# apollo510 register map
Vendor: Ambiq Micro; Series: Apollo; File version: 1.0
CPU: CM55 r1p1, little endian, MPU, FPU, double-precision FPU, DSP, I-cache, D-cache, VTOR, ITCM, DTCM, 4 interrupt priority bits, 0 interrupts, 8 SAU regions
Registers are 32-bit, read-write, reset 0x0 unless marked. A register's access mark holds for its fields unless they carry their own. Offsets are from the block's base; [hi:lo] are bit positions; {n}, {i} and the like mark numbered series; 'fields as' and 'values as' point back to an identical list.

## USB — USB device register descriptions.
Base 0x400B0000
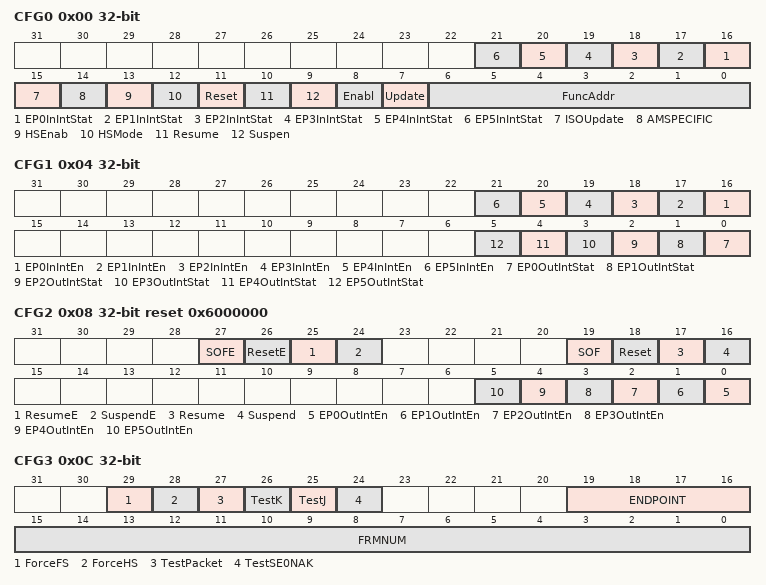
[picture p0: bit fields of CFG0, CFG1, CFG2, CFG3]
0x00 CFG0 — Function address, power management, interrupt status register for EP0 and IN Endpoints 1 to 5
  [n+16] EP{n}InIntStat (n=0..5) — IN Endpoint {n} interrupt status. All interrupts are cleared when the register is read.
    0=INACTIVE (Interrupt inactive.); 1=ACTIVE (Interrupt active.)
  [15] ISOUpdate — Isochronous Transfer Update. When set by the CPU, the USB Controller will wait for an SOF token from the time InPktRdy is set before sending the packet. If an IN token is received before an SOF token, then a zero length data packet will be sent. Note: This bit only affects endpoints performing Isochronous transfers. The ISOUpdate bit affects all IN Isochronous endpoints in the USB Controller. It is normally used as a method of ensuring 'clean' start-up of an IN Isochronous pipe.
    0=DONT_WAIT (Clear for USB Controller not to wait for SOF token before sending packet.); 1=WAIT (Set to have USB Controller wait for SOF token before sending packet.)
  [14] AMSPECIFIC — Software-enabled Connection (SoftConn). When set to 1, the PHY is placed in its normal mode and the D+/D- lines of the USB bus are enabled. When bit is cleared, the PHY is put into non-driving mode and D+ and D- are tri-stated.
    0=NOT_CONNECTED (Clear to disable/disconnect USB lines.); 1=CONNECTED (Set to enable USB lines.)
  [13] HSEnab — High-speed Enable. When set by the CPU, the USB Controller will negotiate for high-speed mode when the device is reset by the hub. If not set, the device will only operate in Full-speed mode. The HSEnab bit can be used to disable high-speed operation. Normally the USB Controller will automatically negotiate for high speed operation, when it is reset, by sending a 'chirp' to the hub. However if this bit is cleared then the USB Controller will not send any 'chirps' to the hub so the function will remain in Full-speed mode, even when connected to a high-speed-capable USB.
    0=DIS_HS (Clear to disable High-speed mode (Full-speed mode only).); 1=EN_HS (Set to enable High-speed mode.)
  [12] HSMode — This read-only bit is set when the USB Controller has successfully negotiated for High-speed mode. The HSMode bit can be used to determine whether the USB Controller is in High-speed mode or Full-speed mode. It will go high when the function has successfully negotiated for high-speed operation during a USB reset.
    0=FS_MODE (Indicates USB Controller is in Full-speed mode only.); 1=HS_MODE (Indicates USB Controller is in High-speed mode.)
  [11] Reset — Reset Status. Cleared when either HS negotiation has completed successfully or after 2.1 ms of reset signaling if HS negotiation fails. The Reset bit can be used to determine when reset signaling is present on the USB. Set when Reset signaling is detected and remains high until the bus reverts to an idle state.
    0=NEG_RESET_COMPLETE (Indicates that HS negotiation has completed successfully, or 2.1 ms of reset signaling has elapsed.); 1=RESETTING (Indicates that Reset signaling is detected and remains high until the bus reverts to an idle state.)
  [10] Resume — Resume. Set should clear this bit after 10 ms (a maximum of 15 ms) to end Resume signaling. The Resume bit is used to force the USB Controller to generate Resume signaling on the USB to perform remote wake-up from Suspend mode. Once set high, it should be left high for approximately 10 ms (at least 1 ms and no more than 15 ms), then cleared.
    0=END_RESUME (Cleared automatically 10-15 ms after being manually set.); 1=RESUME (Set to force USB Controller to generate Resume signal on the USB to cause remote wake-up from Suspend mode.)
  [9] Suspen — Suspend Status. This read-only bit is set when Suspend mode is entered. It is cleared when the CPU reads the interrupt register, or sets the Resume bit of this register. The Suspen bit is set by the USB Controller when Suspend mode is entered. It will be cleared when the CFG2_Suspend field is read (as a result of receiving a Suspend interrupt). It will also be cleared if Suspend mode is left by setting the Resume bit to initiate a remote wake-up.
    0=RESUMED (Indicates that Suspend Mode exited.); 1=SUSPENDED (Indicates that Suspend Mode entered.)
  [8] Enabl — Set by the CPU to enable the SUSPENDM signal. The Enabl bit is set to enable the SUSPENDM signal to put the UTM (and any other hardware which uses the SUSPENDM signal) into Suspend mode. If this bit is not set, Suspend mode will be detected as normal but the SUSPENDM signal will remain high so that the UTM does not go into its low-power mode.
    0=DISABLE_SUSPENDM (Clear to disable SUSPENDM signal - UTM does not go into its low-power mode.); 1=ENABLE_SUSPENDM (Set to enable the SUSPENDM signal to put the UTM (and any other HW which uses the SUSPENDM signal) into Suspend mode.)
  [7] Update — Function Address Update. Set when FuncAddr is written. Cleared when the new address takes effect (at the end of the current transfer).
    0=NEW_ADDR_SET (Indicates that the new address has taken effect.); 1=NEW_ADDR_WRITTEN (Indicates that a new function address has been written to the FuncAddr field.)
  [6:0] FuncAddr — The function address. This field should be written with the address value contained in the SET_ADDRESS standard device request, when it is received on Endpoint 0. The new address will not take effect immediately as the host will still be using the old address for the Status stage of the device request. The USB Controller will continue to use the old address for decoding packets until the device request has completed. The status of the device request can be determined by reading the Update bit. When a new address is written to this field, the Update bit will be automatically set. It will remain high until the device request has completed and will be cleared when the new address takes effect Note: While the firmware may write the new address to the FuncAddr field immediately when it is received, it is recommended to leave this operation to the Status phase of the operation in case the host aborts the command.
0x04 CFG1 — Indicates which of the IN Endpoint 1 - 5 interrupts and the single Endpoint 0 interrupt are currently active. Also indicates which of the interrupts for OUT Endpoint 1 - 5 are currently active. All active interrupts are cleared when this register is read.
  [n+16] EP{n}InIntEn (n=0..5) — IN Endpoint {n} Interrupt Enable
    0=DIS (IN Endpoint interrupt disabled.); 1=EN (IN Endpoint interrupt enabled.)
  [n] EP{n}OutIntStat (n=0..5) — OUT Endpoint {n} interrupt status. All interrupts are cleared when the register is read.
    values as CFG0.EP0InIntStat
0x08 CFG2 reset 0x6000000 — Provides interrupt enable and (currently active) status bits for each of the state interrupts, as well as the IN Endpoint and OUT Endpoint nterrupts. All active interrupts are cleared when this register is read. On reset, all IN and OUT Endpoint interrupts, in addition to Endpoint 0, are set to 1 while the remaining bits are set to 0.
  [27] SOFE — Start of Frame interrupt enable.
    0=DIS (SOF interrupt disable.); 1=EN (SOF interrupt enable.)
  [26] ResetE — Reset Detect Interrupt Enable.
    0=DIS (Reset detect interrupt disable.); 1=EN (Reset detect interrupt enable.)
  [25] ResumeE — Resume Interrupt Enable.
    0=DIS (Resume interrupt disable.); 1=EN (Resume interrupt enable.)
  [24] SuspendE — Suspend Interrupt Enable.
    0=DIS (Suspend interrupt disable.); 1=EN (Suspend interrupt enable.)
  [19] SOF — Start of Frame Interrupt Status. Set at the start of frame.
    0=SOF_INACTIVE (SOF interrupt inactive.); 1=SOF_ACTIVE (SOF interrupt active.)
  [18] Reset — Reset Detect Interrupt Status. Set when reset signaling is detected on the bus.
    0=RESET_INACTIVE (Reset Detect interrupt inactive.); 1=RESET_ACTIVE (Reset Detect interrupt active.)
  [17] Resume — Resume Interrupt Status. Set when resume signaling is detected on the bus while the USB Controller is in Suspend mode.
    0=RESUME_INACTIVE (Resume interrupt inactive.); 1=RESUME_ACTIVE (Resume interrupt active.)
  [16] Suspend — Suspend Interrupt Status. Set when suspend signaling is detected on the bus.
    0=SUSPEND_INACTIVE (Suspend interrupt inactive.); 1=SUSPEND_ACTIVE (Suspend interrupt active.)
  [n] EP{n}OutIntEn (n=0..5) — Out Endpoint {n} Interrupt Enable.
    0=DIS (Out Endpoint interrupt disabled.); 1=EN (Out Endpoint interrupt enabled.)
0x0C CFG3 — Provides Test fields to put the USB Controller into one of four test modes described in the USB 2.0 specification. Only one of the Test fields should be set at any time. (Not used in normal operation.) Also includes an index field that determines which endpoint control,status registers are accessed via the IDXn register fields, and a Frame field that holds the last received frame number.
  [29] ForceFS — Force Full-speed Mode. The CPU sets this bit to force the USB Controller into Full-speed mode when it receives a USB reset.
    0=FS_NOT_FORCED (Do not force FS mode upon USB reset.); 1=FS_FORCED (Force FS mode upon USB reset.)
  [28] ForceHS — Force High-speed Mode. The CPU sets this bit to force the USB Controller into High-speed mode when it receives a USB reset.
    0=HS_NOT_FORCED (Do not force HS mode upon USB reset.); 1=HS_FORCED (Force HS mode upon USB reset.)
  [27] TestPacket — Test Packet Test Mode. The CPU sets this bit to enter the Test_Packet test mode. In this mode, the USB Controller - in high-speed mode - repetitively transmits on the bus a 53-byte test packet. Note: The 53-byte test packet must be loaded into the Endpoint 0 FIFO before the test mode is entered.
    0=STOP_TPTM (Terminates Test Packet Test Mode.); 1=START_TPTM (Initiates Test Packet Test Mode.)
  [26] TestK — Test_K Test Mode. The CPU sets this bit to enter the Test_K test mode. In this mode, the USB Controller - in high-speed mode - transmits a continuous K on the bus.
    0=STOP_TESTK (Terminates Test_K Test Mode.); 1=START_TESTK (Initiates Test_K Test Mode.)
  [25] TestJ — Test_J Test Mode. The CPU sets this bit to enter the Test_J test mode. In this mode, the USB Controller - in high-speed mode - transmits a continuous J on the bus.
    0=STOP_TESTJ (Terminates Test_J Test Mode.); 1=START_TESTJ (Initiates Test_J Test Mode.)
  [24] TestSE0NAK — Test_SE0_NAK Test Mode. The CPU sets this bit to enter the Test_SE0_NAK test mode. In this mode, the USB Controller remains in high-speed mode and responds to any valid IN token with a NAK.
    0=STOP_TESTSE0NAK (Terminates Test_SE0_NAK Test Mode.); 1=START_TESTSE0NAK (Initiates Test_SE0_NAK Test Mode.)
  [19:16] ENDPOINT — Index selected endpoint.
    {v}=Endpoint {v} selected (v=0..5)
  [15:0] FRMNUM — Frame Number. Read-only field containing the last received frame number in bits 10:0, 15:11 read 0.
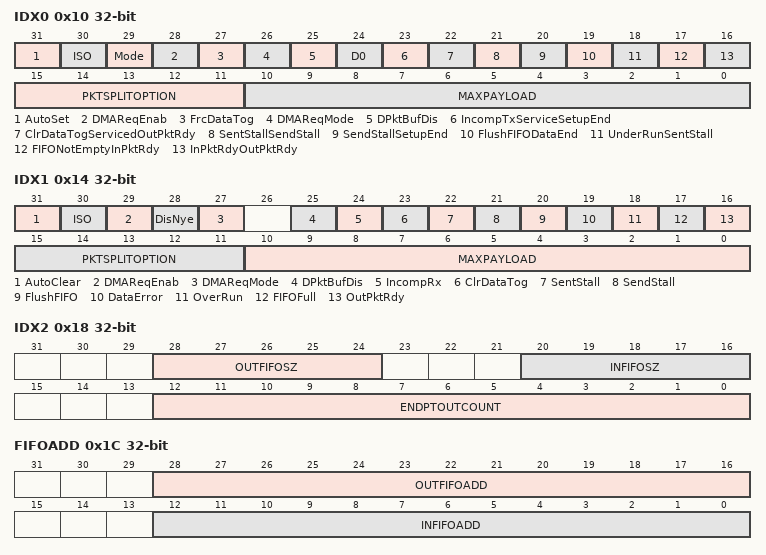
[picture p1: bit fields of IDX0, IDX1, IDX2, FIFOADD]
0x10 IDX0 — Provides additional control and status for IN transactions through the currently-selected endpoint. (To avoid CMSIS conflicts, the address here includes an additional offset of 0x1000. Access to this register must take this into account.) The value returned when this register is read reflects the status of an endpoint specified by setting the endpoint index in the CFG3_ENDPOINT field. When the endpoint index (CFG3_ENDPOINT) == 0, this field provides status and control of Endpoint 0. Also, the MAXPAYLOAD field defines the maximum amount of data that can be transferred through the selected IN endpoint in a single operation. There is a MAXPAYLOAD for each IN endpoint (except Endpoint 0). Note that the action initiated by setting a field in one of the IDXn registers when the selected endpoint has not been configured is undefined.
  [31] AutoSet — Automatically Set InPktRdy. When set, the FIFONotEmptyInPktRdy field (for IN Endpoint 0) or InPktRdyOutPktRdy field (for IN Endpoint 1-5) in this register will be automatically set when data of the maximum packet size (set in MAXPAYLOAD field) is loaded into the IN FIFO.
    0=NO_AUTOSET (InPktRdy field is not automatically set when MAXPAYLOAD data size is loaded into the IN FIFO.); 1=AUTOSET (Applicable InPktRdy field is automatically set when MAXPAYLOAD data size is loaded into the IN FIFO. If a packet of less than the maximum packet size is loaded, InPktRdy will have to be set manually. Note: Should not be set for high-bandwidth Isochronous endpoints.)
  [30] ISO — Isochronous Transfers. The CPU sets this bit to enable the IN endpoint for Isochronous transfers (ISO mode) or for Bulk/Interrupt transfers.
    0=BULK_INT (Clear to enable the IN endpoint for Bulk/Interrupt transfers.); 1=ISO (Set to enable the IN endpoint for Isochronous transfers.)
  [29] Mode — OUT/IN Mode. The CPU sets this bit to enable the endpoint direction as IN or OUT. Note: Only valid where the endpoint FIFO is used for both IN and OUT transactions, otherwise ignored.
    0=OUT (Clear to enable the OUT direction for endpoint.); 1=IN (Set to enable the IN direction for endpoint.)
  [28] DMAReqEnab — The CPU sets this bit to enable the DMA request for the IN endpoint.
  [27] FrcDataTog — Force Data Toggle. The CPU sets this bit to force the endpoint's IN data toggle to switch after each data packet is sent regardless of whether an ACK was received. This can be used by Interrupt IN endpoints that are used to communicate rate feedback for Isochronous endpoints.
    0=NO_FORCE_TOGGLE (Keep cleared to not force data toggle.); 1=FORCE_TOGGLE (Set to force the endpoint's IN data toggle to switch after each data packet is sent.)
  [26] DMAReqMode — The CPU sets this bit to select DMA Request Mode 1 and clears it to select DMA Request Mode 0. Note: This bit must not be cleared either before or in the same cycle as the above DMAReqEnab bit is cleared.
  [25] DPktBufDis — Double Packet Buffer Disable. This bit is used to control the use of Double Packet Buffering. It is ignored when Dynamic FIFO sizing is enabled. Clearing this bit does NOT necessarily enable Double Packet Buffering but rather allows Double Packet Buffering to be determined by the Endpoint's IDX2_INFIFOSZ setting and MAXPAYLOAD size relationship. Default is enabled.
    0=EN_DPB (Clear to allow Double Packet Buffering.); 1=DIS_DPB (Set to disable Double Packet Buffering regardless of the End Point FIFO size and MAXPAYLOAD size relationship.)
  [24] D0 — Unused, always return 0.
  [23] IncompTxServiceSetupEnd — Incomplete Transmission / Service Setup End. When CFG3_ENDPOINT is 1 to 5, this bit serves as the IncompTx field. When CFG3_ENDPOINT is 0, this bit serves as the ServiceSetupEnd field.If CFG3_ENDPOINT is 0x1-0x5, then this bit serves as the IncompTx field. If the endpoint is being used for high-bandwidth Isochronous transfers, this bit is set to indicate when a large packet has been split into 2 or 3 packets for transmission but insufficient IN tokens have been received to send all the parts. The remainder of the current packet is then flushed from the FIFO (but any second packet in the FIFO will remain). Note: In anything other than a high bandwidth Isochronous transfer, this bit will always return 0.
    0=NOP (This value is a NOP.); 1=CLR_SETUPEND (Set to clear the SetupEnd bit. This bit is cleared automatically.)
  [22] ClrDataTogServicedOutPktRdy — Clear Data Toggle / Serviced OUT Packet Ready. When CFG3_ENDPOINT is 1 to 5, this bit serves as the ClrDataTog field. When CFG3_ENDPOINT is 0, this bit serves as the ServicedOutPktReady field.If CFG3_ENDPOINT is 0x1-0x5, this bit serves as the ClrDataTog field. Setting this bit resets the endpoint IN data toggle to 0.If CFG3_ENDPOINT is 0x0, this bit serves as the ServicedOutPktReady field. The CPU writes a 1 to this bit to clear the OutPktRdy bit. This bit is cleared automatically.
  [21] SentStallSendStall — Sent Stall / Send Stall. When CFG3_ENDPOINT is 1 to 5, this bit serves as the SentStall field. When CFG3_ENDPOINT is 0, this bit serves as the SendStall function.If CFG3_ENDPOINT is 0x1-0x5, this bit serves as the SentStall field. It is set when a STALL handshake is transmitted. The FIFO is flushed and the InPktRdy bit is cleared. The CPU should clear this bit.If CFG3_ENDPOINT is 0x0, this bit serves as the SendStall field. The CPU sets this bit to terminate the current transaction. The STALL handshake will be transmitted and then this bit will be cleared automatically. Note: This behavior differs from that of the SendStall bits associated with additional IN/OUT endpoints, which need to be cleared by the CPU.
  [20] SendStallSetupEnd — When CFG3_ENDPOINT is 1 to 5, this bit serves as the SendStall field. When CFG3_ENDPOINT is 0, this bit serves as the SetupEnd field.If CFG3_ENDPOINT is 0x1-0x5, this bit serves as the SendStall field. Setting this bit issues a STALL handshake to an IN token. The CPU clears this bit to terminate the stall condition.Note: This bit has no effect when the endpoint is being used for Isochronous transfers.If CFG3_ENDPOINT is 0x0, this bit serves as the SetupEnd field. It is set when a control transaction ends before the DataEnd bit has been set. An interrupt will be generated and the FIFO flushed at this time. The bit is cleared by the CPU writing a 1 to the ServicedSetupEnd bit.
  [19] FlushFIFODataEnd — When CFG3_ENDPOINT is 1 to 5, this bit serves as the FlushFIFO field. When CFG3_ENDPOINT is 0, this bit serves as the DataEnd bit.If CFG3_ENDPOINT is 0x1-0x5, this bit serves as the FlushFIFO field. Setting this bit flushes the next packet to be transmitted from the endpoint IN FIFO. The FIFO pointer is reset and the InPktRdy bit is cleared. May be set simultaneously with InPktRdy to abort the packet that has just been loaded into the FIFO.Note 1: FlushFIFO should only be set when InPktRdy is set (at other times, it may cause data corruption).Note 2: If the FIFO contains two packets, FlushFIFO may need to be set twice to completely clear the FIFO.If CFG3_ENDPOINT is 0x0, this bit serves as the DataEnd bit. Set this bit when (1) setting InPktRdy for the last data packet, (2) clearing OutPktRdy after unloading the last data packet, or (3) setting InPktRdy for a zero length data packet.It is cleared automatically.
  [18] UnderRunSentStall — Under Run / Sent Stall. When CFG3_ENDPOINT is 1 to 5, this bit serves as the UnderRun field. When CFG3_ENDPOINT is 0, this bit serves as the SentStall field.If CFG3_ENDPOINT is 0x1-0x5, this bit serves as the UnderRun field. In ISO mode this bit is set when a zero length data packet is sent after receiving an IN token with the InPktRdy bit not set. In Bulk/Interrupt mode, this bit is set when a NAK is returned in response to an IN token. The CPU should clear this bit.If CFG3_ENDPOINT is 0x0, this bit serves as the SentStall field. This bit is set when a STALL handshake is transmitted. The CPU should clear this bit.
  [17] FIFONotEmptyInPktRdy — FIFO Not Empty / IN Packet Ready. When CFG3_ENDPOINT is 1 to 5, this bit serves as the FIFONotEmpty field. When CFG3_ENDPOINT is 0, this bit serves as the InPktRdy bit.If CFG3_ENDPOINT is 0x1-0x5, this bit serves as the FIFONotEmpty field. It is set when there is at least 1 packet in the IN FIFO.If CFG3_ENDPOINT is 0x0, this bit serves as the InPktRdy bit. Set this bit after loading a data packet into the FIFO. It is cleared automatically when the data packet has been transmitted. An interrupt is generated when this bit is cleared (if enabled).
  [16] InPktRdyOutPktRdy — IN Packet Ready / OUT Packet Ready. When CFG3_ENDPOINT > 0, this bit serves as the InPktRdy field. When CFG3_ENDPOINT is 0, this bit serves as the OutPkyRdy bit.If CFG3_ENDPOINT is 0x1-0x5, this bit serves as the InPktRdy field. Set this bit after loading a data packet into the FIFO. It is cleared automatically when a data packet has been transmitted. If the FIFO is double-buffered, it is also automatically cleared when there is space for a second packet in the FIFO. An interrupt is generate (if enabled) when the bit is cleared.If CFG3_ENDPOINT is 0x0, this bit serves as the OutPkyRdy bit. This bit is set when a data packet has been received. An interrupt is generate when this bit is set (if enabled). The CPU clears this bit by setting the ServicedOutPktRdy bit.
  [15:11] PKTSPLITOPTION — Packet Split Option. When IDX0_ISO is 1, this bit serves as the MAXPAYLOAD multiplier for Isochronous IN transfers. When IDX0_ISO is 0, this bit serves as the MAXPAYLOAD multiplier for Bulk IN transfers.If IDX0_ISO is 0x1, this field sets the multiplier for Isochronous transfers. For Isochronous endpoints operating in High-Speed mode and with the High-bandwidth option enabled, PKTSPLITOPTION may be either 2 or 3 (corresponding to this field's bit 0 set or bit 1 set, respectively, and bits[4:2] are ignored) and it specifies the maximum number of such transactions that can take place in a single microframe. If either bit 0 or bit 1 is non-zero, the USB Controller will automatically split any data packet written to the FIFO into up to 2 or 3 'USB' packets, each containing the specified MAXPAYLOAD (or less). The maximum payload for each transaction is 1024 bytes, so this allows up to 3072 bytes to be transmitted in each microframe. (For Isochronous transfers in full-speed mode or if High-bandwidth is not enabled, bits 0 and 1 are ignored.)If IDX0_ISO is 0x0, this field sets the multiplier for Bulk transfers. The field setting can be up to 31, and the multiplier, m, is (field setting + 1). The multiplier defines the maximum number of 'USB' packets of the specified MAXPAYLOAD data bytes into which a single data packet placed in the FIFO should be split prior to transfer. The data packet is required to be an exact multiple of the MAXPAYLOAD, which is itself required to be either 8, 16, 32, 64 or (in the case of High Speed transfers) 512 bytes.
  [10:0] MAXPAYLOAD — Maximum Payload transmitted in a single transaction. The total amount of data represented by MAXPAYLOAD x (PKTSPLITOPTION + 1) must not exceed the FIFO size for the IN endpoint, and should not exceed half the FIFO size if double-buffering is required. Note: The value written here (multiplied by PKTSPLITOPTION + 1 in the case of high-bandwidth Isochronous transfers) must match the value given in the wMaxPacketSize field of the Standard Endpoint Descriptor for the associated endpoint (see USB Specification Revision 2.0, Chapter 9). A mismatch could cause unexpected results.
0x14 IDX1 — Provides control and status bits for OUT transactions through the currently-selected endpoint. It is reset to 0. The value returned when this register is read reflects the status of an endpoint specified by setting the endpoint index in the CFG3_ENDPOINT field. Also, the MAXPAYLOAD field defines the maximum amount of data that can be transferred through the selected OUT endpoint in a single operation. There is a MAXPAYLOAD for each OUT endpoint (except Endpoint 0). Note that the action initiated by setting a field in one of the IDXn registers when the selected endpoint has not been configured is undefined.
  [31] AutoClear — Automatically Clear OutPktRdy.
    0=NO_AUTOCLR (OutPktRdy field will not be automatically cleared when a packet of MAXPAYLOAD data size is unloaded from the OUT FIFO.); 1=AUTOCLR (OutPktRdy field will be automatically cleared when a packet of MAXPAYLOAD data size is unloaded from the OUT FIFO. When packets of less than the maximum packet size are unloaded, OutPktRdy must be cleared manually. Note: Should not be set for high bandwidth Isochronous endpoints.)
  [30] ISO — Isochronous Transfers. The CPU sets this bit to enable the OUT endpoint for either Isochronous transfers (ISO mode) or for Bulk/Interrupt transfers.
    0=BULK_INT (Clear to enable the OUT endpoint for Bulk/Interrupt transfers.); 1=ISO (Set to enable the OUT endpoint for Isochronous transfers.)
  [29] DMAReqEnab — Set this bit to enable the DMA request for the OUT endpoint.
  [28] DisNye — Disable NYET Handshakes / PID Error. For Bulk/Interrupt transactions, this bit disable the sending of NYET handshakes. For Bulk/Interrupt transactions, indicates PID errors.If IDX1_ISO is 0x1, this field is read-only and, when set, indicates a PID error in the received packet for Isochronous transfers.If IDX1_ISO is 0x0, this field disables NYET Handshakes for Bulk/Interrupt transactions. Set this bit to disable the sending of NYET handshakes. When set, all successfully received OUT packets are ACK'd including at the point at which the FIFO becomes full.Note: This bit has an effect only in High-speed mode, when it should be set for all Interrupt endpoints.
  [27] DMAReqMode — Two modes of DMA Request operation are supported: Set to 0 for DMA Request Mode 0 in which a DMA request is generated for all received packets; set to 1 for DMA Request Mode 1 in which a DMA request (but no interrupt) is generated for OUT packets of size MAXPAYLOAD bytes and an interrupt (but no DMA request) is generated for OUT packets of any other size.
  [25] DPktBufDis — Double Packet Buffer Disable. This bit is used to control the use of Double Packet Buffering. It is ignored when Dynamic FIFO sizing is enabled. Clearing this bit does NOT necessarily enable Double Packet Buffering but rather allows Double Packet Buffering to be determined by the Endpoint's IDX2_OUTFIFOSZ setting and MAXPAYLOAD size relationship. Default is enabled.
    values as IDX0.DPktBufDis
  [24] IncompRx — Incomplete Receive. This bit is set in a high-bandwidth Isochronous transfer if the packet in the OUT FIFO is incomplete because parts of the data were not received. It is cleared when OutPktRdy is cleared. Note: In anything other than a high-bandwidth Isochronous transfer, this bit will always return 0.
  [23] ClrDataTog — Clear Data Toggle. Set this bit to reset the endpoint data toggle to 0.
  [22] SentStall — Sent Stall. This bit is set when a STALL handshake is transmitted. The CPU should clear this bit.
  [21] SendStall — Send Stall. Issues a STALL handshake to a DATA packet.If IDX1_ISO is 0x1, this bit has no effect when the endpoint is being used for Isochronous transfers.If IDX1_ISO is 0x0, this field enables Stall Handshakes for Bulk/Interrupt transactions. Set this bit to issue a STALL handshake to a DATA packet. Clear this bit to terminate the stall condition.
  [20] FlushFIFO — Flush FIFO. Set this bit to flush the next packet to be read from the endpoint OUT FIFO. The FIFO pointer is reset and the OutPktRdy bit is cleared. FlushFIFO should only be used when OutPktRdy is set. At other times, it may cause data to be corrupted. If the FIFO is double-buffered, FlushFIFO may need to be set twice to completely clear the FIFO.
  [19] DataError — Data Error. Indicates a CRC error.If IDX1_ISO is 0x1 (ISO mode), this bit is set at the same time that OutPktRdy is set if the data packet has a CRC error. It is cleared when OutPktRdy is cleared.If IDX1_ISO is 0x0 (Bulk mode), this field always returns zero. This field is only valid when the endpoint is operating in ISO mode.
  [18] OverRun — Overrun Condition. Indicates an overrun.If IDX1_ISO is 0x1 (ISO mode), this bit is set if an OUT packet arrives while FIFOFull is set, i.e., the OUT packet cannot be loaded into the OUT FIFO. The CPU should clear this bit.If IDX1_ISO is 0x0 (Bulk mode), this field always returns zero. This field is only valid when the endpoint is operating in ISO mode.
  [17] FIFOFull — FIFO Full. When set, this bit indicates that no more packets can be loaded into the OUT FIFO.
  [16] OutPktRdy — OUT Packet Ready. This bit is set when a data packet has been received. Clear this bit when the packet has been unloaded from the OUT FIFO. An interrupt is generated (if enabled) when the bit is set.
  [15:11] PKTSPLITOPTION — Packet Split Option. When IDX1_ISO is 1, this bit serves as the MAXPAYLOAD multiplier for Isochronous OUT transfers. When IDX1_ISO is 0, this bit serves as the MAXPAYLOAD multiplier for Bulk IN transfers.If IDX1_ISO is 0x1, this field sets the multiplier for Isochronous transfers. For Isochronous endpoints operating in High-Speed mode and with the High-bandwidth option enabled, PKTSPLITOPTION may be either 2 or 3 (corresponding to this field's bit 0 set or bit 1 set, respectively, and bits[4:2] are ignored) and it specifies the maximum number of such transactions that can take place in a single microframe. If either bit 0 or bit 1 is non-zero, the USB Controller will automatically combine the separate USB packets received in any microframe into a single packet within the OUT FIFO. The maximum payload for each transaction is 1024 bytes, so this allows up to 3072 bytes to be received in each microframe. (For Isochronous transfers in full-speed mode or if high-bandwidth is not enabled, bits 0 and 1 are ignored.)If IDX1_ISO is 0x0, this field sets the multiplier for Bulk transfers. The field setting can be up to 31, and the multiplier, m, is (field setting + 1). The multiplier defines the number of USB packets of the specified payload which are to be combined into a single data packet within the FIFO.
  [10:0] MAXPAYLOAD — Maximum Payload transmitted in a single transaction. The value set can be up to 1024 bytes but is subject to the constraints placed by the USB Specification on packet sizes for Bulk, Interrupt and Isochronous transfers in Fullspeed and High-speed operations. The total amount of data represented by MAXPAYLOAD x (PKTSPLITOPTION + 1) must not exceed the FIFO size for the OUT endpoint, and should not exceed half the FIFO size if double-buffering is required. Note: The value written here (multiplied by m in the case of high-bandwidth Isochronous transfers) must match the value given in the wMaxPacketSize field of the Standard Endpoint Descriptor for the associated endpoint (see USB Specification Revision 2.0, Chapter 9). A mismatch could cause nexpected results.
0x18 IDX2 — Contains the outcount value for number of received bytes in the packet in the OUT FIFO, and the configurable IN and OUT Endpoint FIFO size.
  [28:24] OUTFIFOSZ — OUT FIFO Size. Sets the size of the selected OUT endpoint FIFO. Bit 4 of this field defines whether double-packet buffering is supported. When set, double-packet buffering is supported. When cleared, only single-packet buffering is supported. Bits [3:0] of this field determine maximum packet size, where 2^^(b3:b0 + 3) is the maximum packet size to be allowed (before any splitting within the FIFO of Bulk/High-Bandwidth packets prior to transmission).
  [20:16] INFIFOSZ — IN FIFO Size. Sets the size of the selected IN endpoint FIFO. Bit 4 of this field defines whether double-packet buffering supported. When set, double-packet buffering is supported. When cleared, only single-packet buffering is supported. Bits [3:0] of this field determine maximum packet size, where 2^^(b3:b0 + 3) is the maximum packet size to be allowed (before any splitting within the FIFO of Bulk/High-Bandwidth packets prior to transmission).
  [12:0] ENDPTOUTCOUNT — Endpoint OUT Count. When CFG3_ENDPOINT is 1 to 5, this read-only field holds the number of received data bytes in the packet in the Endpoint's OUT FIFO. When CFG3_ENDPOINT is 0, this read-only field holds 7-bit data for number of received data bytes in Endpoint 0 FIFO (OUT count). In either case, the value returned changes as the contents of the FIFO change and is only valid while OutPktRdy is set. (IMPORTANT: The address for the OUTCOUNT register is actually the same as COUNT0. However to avoid CMSIS conflicts, the address here includes an additional offset of 0x1000. Access to this register must take this into account.)If CFG3_ENDPOINT is 0x1-0x5, this read-only field holds the number of received data bytes in the packet in the OUT FIFO. If the packet was transmitted as multiple bulk packets, the number given will be for the combined packet.If CFG3_ENDPOINT is 0x0, this read-only field holds 7-bit data for number of received data bytes in Endpoint 0 FIFO (OUT count).
0x1C FIFOADD — Sets the start address of the selected IN and OUT endpoint FIFOs.
  [28:16] OUTFIFOADD — Sets the start address of the selected OUT endpoint FIFO.
  [12:0] INFIFOADD — Sets the start address of the selected IN endpoint FIFO.
{0x20+4i} FIFO{i} (i=0..5) — Endpoint {i} FIFO register
  [31:0] FIFO — Writing to this register loads data into the IN FIFO and reading from this register unloads data from the OUT FIFO for endpoint {i}.
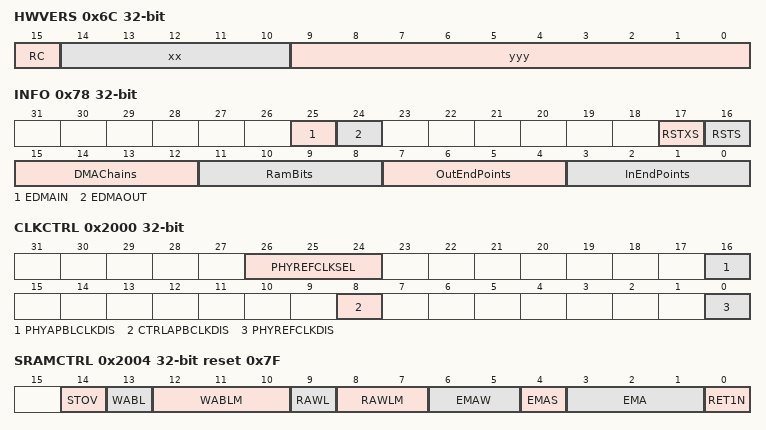
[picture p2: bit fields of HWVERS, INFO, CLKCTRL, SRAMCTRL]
0x6C HWVERS — Read-only register that returns version number (xx.yyy) of the core hardware.
  [15] RC — Unused
  [14:10] xx — Major Version Number (Range 0 - 31).
  [9:0] yyy — Minor Version Number (Range 0 - 999).
0x78 INFO — Contains read-only info of the number of IN and OUT endpoints included in the design, width of the RAM, the ability to reset the USB Controller via software, a soft reset bit for the CLK clock domain and a soft reset bit for the XCLK clock domain.
  [25] EDMAIN — DMA_REQ deassert for all IN endpoints.
    0=DEASSERT_MAXPAYLOAD (DMA_REQ signal for all IN Endpoints will be de-asserted when MAXPAYLOAD bytes have been written to an endpoint.); 1=DEASSERT_MAXPAYLOADMINUS8 (DMA_REQ signal for all IN Endpoints will be de-asserted when MAXPAYLOAD-8 bytes have been written to an endpoint.)
  [24] EDMAOUT — DMA_REQ deassert for all OUT Endpoints.
    0=DEASSERT_MAXPAYLOAD (DMA_REQ signal for all OUT Endpoints will be de-asserted when MAXPAYLOAD bytes have been read to an endpoint. When 1 byte early.); 1=DEASSERT_MAXPAYLOADMINUS8 (DMA_REQ signal for all OUT Endpoints will be de-asserted when MAXPAYLOAD-8 bytes have been read to an endpoint. When 1 byte early.)
  [17] RSTXS — Soft reset for the XCLK domain. will cause the output signal NRSTXO to be asserted low. This bit is self-clearing. For reset to actually occur, the output NRSTXO must be connected to the input NRSTX.
  [16] RSTS — Soft reset for the CLK domain. cause the output signal NRSTO to be asserted low. This bit is self-clearing. For reset to actually occur, the output NRSTO must be connected to the input NRST.
  [15:12] DMAChains — Provides the number of implemented DMA channels.
  [11:8] RamBits — Provides the width of the RAM address bus.
  [7:4] OutEndPoints — Provides the number of implemented OUT Endpoints.
  [3:0] InEndPoints — Provides the number of implemented IN Endpoints.
0x80 TIMEOUT1 reset 0x4074 — Holds the configurable chirp timeout value.
  [15:0] CTUCH — Configurable Chirp Timeout timer; default value of 0x4074 corresponds to a delay of 1.1ms (60Mhz clock cycles * 4 * 0x4074).
0x84 TIMEOUT2 reset 0x32 — Holds the configurable delay from the end of High Speed resume signal to enable UTM normal operating mode.
  [15:0] CTHRSTN — Configurable delay from the end of High Speed resume signaling to enabling UTM normal operating mode. Default value of 0x32 corresponds to a delay of 3us. This programmed delay is equivalent to the number of 60MHz clock cycles * 4.
0x2000 CLKCTRL — Provides optional control for turning off the interface clocks to USB Controller and PHY as well as the reference clock to the USB PHY.
  [26:24] PHYREFCLKSEL — USB PHY reference clock select. The reference clock frequency needs to be 24MHz.
    0=HFRC_48MHz (48MHz HFRC. Internally will divide by 2 before using it as USB PHY reference clock.); 1=HFRC2_31MHz (31MHz HFRC2. Internally will divide by 2 before using it as USB PHY reference clock. This is only for engineering purpose, as it does not meet the 24MHz frequency requirement.); 2=HFRC_24MHz (24MHz HFRC based reference clock); 3=EXTREFCLK (External reference clock); 4=EXTREFCLK_DIV2 (External reference clock divide by 2); 5=XTALHS (XTAL clock as reference clock); 6=XTALHS_DIV2 (XTAL clock divide by 2 as reference clock); 7=OFF (Static 0)
  [16] PHYAPBLCLKDIS — Setting this bit turns off PHY control logic clock.
  [8] CTRLAPBCLKDIS — Setting this bit turns off the Controller logic clock.
  [0] PHYREFCLKDIS — Setting this bit turns off the PHY reference clock.
0x2004 SRAMCTRL reset 0x7F — Provides optional SRAM tuning control.
  [14] STOV — SRAM self-timed override
  [13] WABL — SRAM write assist enable
  [12:10] WABLM — SRAM No margin adjustment
  [9] RAWL — SRAM Read assist enable
  [8:7] RAWLM — SRAM Adjustment for margin for this read assist scheme
    3=INCDLY (Increased margin adjustment, increased delay for enabling write assist.); 2=MBINCDLY (Minimum boost level with increased delay for enabling write assist.); 1=IMNB (Increased margin adjustment with more negative boost.); 0=MMNB (Minimum margin adjustment with lowest negative boost level.)
  [6:5] EMAW — Extra margin adjustment for write operations
  [4] EMAS — Extra margin adjustment sense amplifier pulse
  [3:1] EMA — Extra margin adjustment
  [0] RET1N — Retention mode 1 enable, active-LOW
0x2014 UTMISTICKYSTATUS — This read only register provides the results from the PHY OBS port controlled by reg 0x20[5:4]. IF any bits are set, the bits are sticky. Clear this register using the OBSCLRSTAT register.
  [1:0] OBSPORTSTICKY — These bits are read only status bits from the PHY OBS port
    3=OBS3 (bit 1:HS BIST results, bit 0:FS BIST results); 2=OBS2 (bit 1: ODT calibration state, bit 0: Current calibration state); 1=OBS1 (bit 1: Rx squelch signal, bit 0: Rx datap); 0=OBS0 (bit 1: PLL lock signal, bit 0: Host Disconnect)
0x2018 OBSCLRSTAT — Clears all bits in the sticky obs status register.
  [0] CLRSTAT — Writing a 1 to this bit clears all bits in the UTMISTICKYSTATUS register.
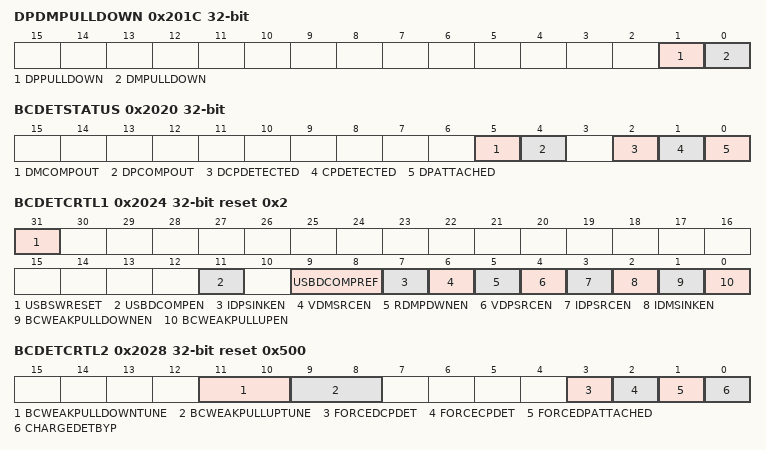
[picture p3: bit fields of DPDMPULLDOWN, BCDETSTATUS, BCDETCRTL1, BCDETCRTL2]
0x201C DPDMPULLDOWN — Enables a pulldown resistor(15K) on D+ or D-
  [1] DPPULLDOWN — Enables a pulldown resistor(15K) on D+
  [0] DMPULLDOWN — Enables a pulldown resistor(15K) on D-
0x2020 BCDETSTATUS — USB Battery Charge Detenction Registers
  [5] DMCOMPOUT — DM comparator output
  [4] DPCOMPOUT — DP comparator output
  [2] DCPDETECTED — Dedicated charging port detected
  [1] CPDETECTED — Charging port detected
  [0] DPATTACHED — Data pin attachment detected
0x2024 BCDETCRTL1 reset 0x2 — Battery Charging detection main control register
  [31] USBSWRESET — Holds a USB controller and PHY in the reset for BC detection
  [11] USBDCOMPEN — Enables DP/DM vendor-specific detection comparator
  [9:8] USBDCOMPREF — Sets DP/DM vendor-specific comparator ref voltage
    3=1P25V (1.25V); 2=2P35 (2.35V); 1=3P10V (3.10V); 0=1P65 (1.65V (VCCIO/2))
  [7] IDPSINKEN — Enables DP current sink
  [6] VDMSRCEN — Enables DM voltage source
  [5] RDMPDWNEN — Enables DM BC 1.2 pull-down resistor
  [4] VDPSRCEN — Enables DP voltage source
  [3] IDPSRCEN — Enables DP current source
  [2] IDMSINKEN — Enables DM current sink
  [1] BCWEAKPULLDOWNEN — Enables weak sink current on DP and DM
  [0] BCWEAKPULLUPEN — Enables weak source current to DP and DM
0x2028 BCDETCRTL2 reset 0x500 — Battery Charging auxillary detection control register
  [11:10] BCWEAKPULLDOWNTUNE — Weak sink resistor to both DP and DM tuning. Trimmable.
  [9:8] BCWEAKPULLUPTUNE — Weak source resistor to both DP and DM tuning. Trimmable.
  [3] FORCEDCPDET — Force output dedicated charging port detected
  [2] FORCECPDET — Force output charging port detected
  [1] FORCEDPATTACHED — Force output dp_attached
  [0] CHARGEDETBYP — BC detection bypass
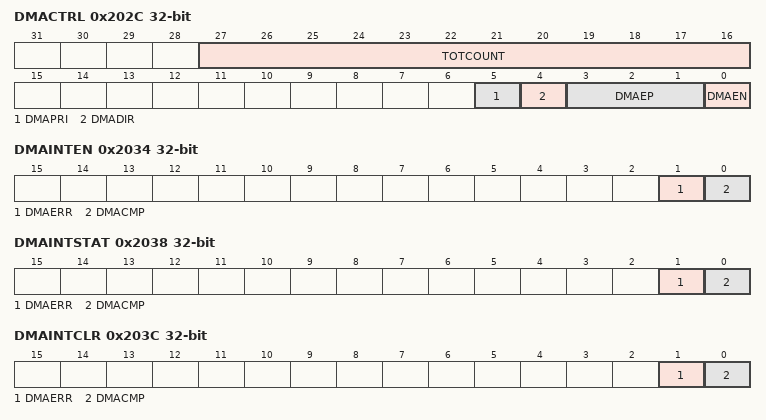
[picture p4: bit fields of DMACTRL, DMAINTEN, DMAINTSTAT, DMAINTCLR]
0x202C DMACTRL — DMA Control
  [27:16] TOTCOUNT — total transfer count in bytes
  [5] DMAPRI — USB DMA priority
  [4] DMADIR — USB DMA direction
  [3:1] DMAEP — USB DMA endpoint selection
  [0] DMAEN — enable USB DMA
0x2030 DMATARGADDR — USB DMA Target Address
  [31:0] TARGADDR — Target byte address for source of DMA (either read or write). In cases of non-word aligned addresses, the DMA logic will take care for ensuring only the target bytes are read/written.
0x2034 DMAINTEN — Set bits in this register to allow this module to generate the corresponding interrupt.
  [1] DMAERR — DMA Error Interrupt
  [0] DMACMP — DMA Complete Interrupt
0x2038 DMAINTSTAT — Read bits from this register to discover the cause of a recent interrupt.
  fields as DMAINTEN
0x203C DMAINTCLR — Write a 1 to a bit in this register to clear the interrupt status associated with that bit.
  fields as DMAINTEN
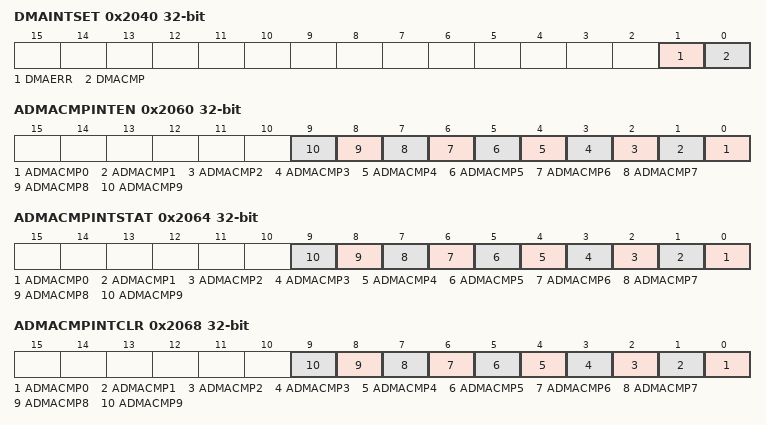
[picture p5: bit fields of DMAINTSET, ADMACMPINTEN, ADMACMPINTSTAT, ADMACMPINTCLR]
0x2040 DMAINTSET — Write a 1 to a bit in this register to instantly generate an interrupt from this module. (Generally used for testing purposes).
  fields as DMAINTEN
0x2044 ADMACTRL — Auto-DMA Control
  [0] DMAMODE — 0 - Legacy DMA mode, 1 - Auto-DMA mode
0x2048 ADMAEN — Auto DMA Enable Register
  [9:0] ADMAEN — Set ADMAEN[i] to 1 to enable auto-DMA for USB DMA request line [i].
0x204C ADMADIR — Auto DMA Direction Select Register
  [9:0] ADMADIR — Set ADMADIR[i] to 0 for OUT, and 1 for IN direction for auto-DMA for USB DMA request line [i].
0x2050 ADMAPRI — Auto DMA Priority Select Register
  [9:0] ADMAPRI — Set ADMAPRI[i] to 1 to set the priority for auto-DMA for USB DMA request line [i].
0x2060 ADMACMPINTEN — Set bits in this register to allow this module to generate the corresponding interrupt.
  [n] ADMACMP{n} (n=0..9) — ADMA Complete for USB DMA request line {n} Interrupt
0x2064 ADMACMPINTSTAT — Read bits from this register to discover the cause of a recent interrupt.
  fields as ADMACMPINTEN
0x2068 ADMACMPINTCLR — Write a 1 to a bit in this register to clear the interrupt status associated with that bit.
  fields as ADMACMPINTEN
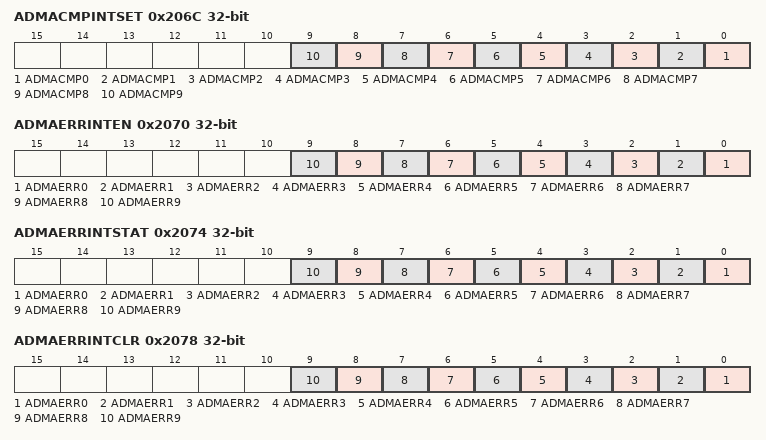
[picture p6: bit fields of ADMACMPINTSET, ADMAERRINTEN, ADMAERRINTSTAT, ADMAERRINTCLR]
0x206C ADMACMPINTSET — Write a 1 to a bit in this register to instantly generate an interrupt from this module. (Generally used for testing purposes).
  fields as ADMACMPINTEN
0x2070 ADMAERRINTEN — Set bits in this register to allow this module to generate the corresponding interrupt.
  [n] ADMAERR{n} (n=0..9) — ADMA Error for USB DMA request line {n} Interrupt
0x2074 ADMAERRINTSTAT — Read bits from this register to discover the cause of a recent interrupt.
  fields as ADMAERRINTEN
0x2078 ADMAERRINTCLR — Write a 1 to a bit in this register to clear the interrupt status associated with that bit.
  fields as ADMAERRINTEN
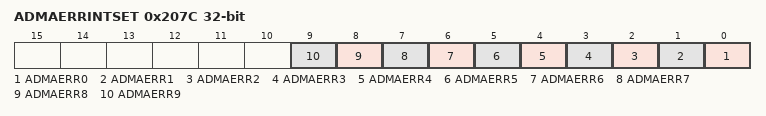
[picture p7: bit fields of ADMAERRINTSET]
0x207C ADMAERRINTSET — Write a 1 to a bit in this register to instantly generate an interrupt from this module. (Generally used for testing purposes).
  fields as ADMAERRINTEN
{0x2100+4i} ADMATOTCOUNT{i} (i=0..9) — Auto DMA Enable Register
  [23:0] ADMATOTCOUNT{i} — Auto DMA Total Count for USB DMA request line {i}
{0x2200+4i} ADMATARGADDR{i} (i=0..9) — Auto DMA Target Address {i}
  [31:0] ADMATARGADDR{i} — Auto DMA Target Address for USB DMA request line {i}
{0x2300+4i} ADMAEP{i} (i=0..9) — Auto DMA EP Number {i}
  [2:0] ADMAEP{i} — Auto DMA EP Number for USB DMA request line {i}
{0x2400+4i} ADMAREQSIZE{i} (i=0..9) — Auto DMA Request Size {i}
  [11:0] ADMAREQSIZE{i} — Auto DMA Request Size for USB DMA request line {i}
